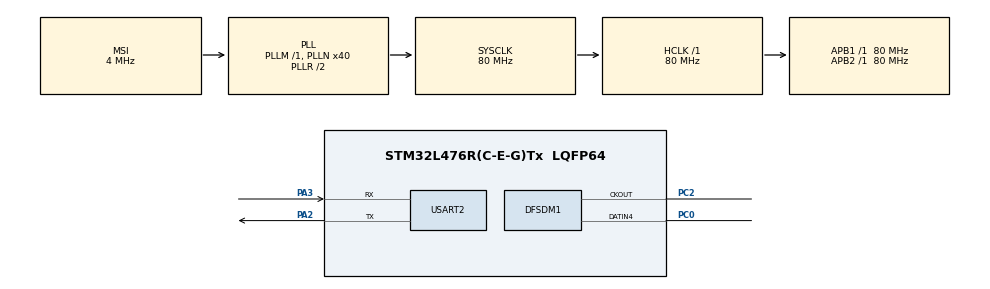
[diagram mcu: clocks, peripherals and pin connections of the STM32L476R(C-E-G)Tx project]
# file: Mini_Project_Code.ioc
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DFSDM1.Divider=32
DFSDM1.DmaMode_reg_FIL0=ENABLE
DFSDM1.FastMode_reg_FIL0=ENABLE
DFSDM1.Filter_regChannel_FIL0=DFSDM_CHANNEL_3
DFSDM1.Filter_regChannel_FIL1=__NULL
DFSDM1.Fosr_FIL0=38
DFSDM1.Iosr_FIL0=4
DFSDM1.SincOrder_FIL0=DFSDM_FILTER_SINC4_ORDER
Dma.DFSDM1_FLT0.0.Direction=DMA_PERIPH_TO_MEMORY
Dma.DFSDM1_FLT0.0.Instance=DMA1_Channel4
Dma.DFSDM1_FLT0.0.MemDataAlignment=DMA_MDATAALIGN_WORD
Dma.DFSDM1_FLT0.0.MemInc=DMA_MINC_ENABLE
Dma.DFSDM1_FLT0.0.Mode=DMA_NORMAL
Dma.DFSDM1_FLT0.0.PeriphDataAlignment=DMA_PDATAALIGN_WORD
Dma.DFSDM1_FLT0.0.PeriphInc=DMA_PINC_DISABLE
Dma.DFSDM1_FLT0.0.Priority=DMA_PRIORITY_LOW
Dma.Request0=DFSDM1_FLT0
Mcu.Family=STM32L4
Mcu.Name=STM32L476R(C-E-G)Tx
Mcu.Package=LQFP64
NVIC.DMA1_Channel4_IRQn=true\:0\:0\:false\:false\:true\:false\:true\:true
NVIC.PriorityGroup=NVIC_PRIORITYGROUP_4
NVIC.TIM2_IRQn=true\:0\:0\:false\:false\:true\:true\:true\:true
PA2.Mode=Asynchronous
PA2.Signal=USART2_TX
PA3.Mode=Asynchronous
PA3.Signal=USART2_RX
PC0.Signal=S_DATAIN4DFSDM1
PC2.Signal=S_CKOUTDFSDM1
ProjectManager.HeapSize=0x200
ProjectManager.StackSize=0x400
ProjectManager.TargetToolchain=CMake
RCC.AHBFreq_Value=80000000
RCC.APB1Freq_Value=80000000
RCC.APB1TimFreq_Value=80000000
RCC.APB2Freq_Value=80000000
RCC.APB2TimFreq_Value=80000000
RCC.CortexFreq_Value=80000000
RCC.HCLKFreq_Value=80000000
RCC.HSE_VALUE=8000000
RCC.HSI_VALUE=16000000
RCC.LSE_VALUE=32768
RCC.MSI_VALUE=4000000
RCC.PLLN=40
RCC.SYSCLKFreq_VALUE=80000000
RCC.SYSCLKSource=RCC_SYSCLKSOURCE_PLLCLK
RCC.VCOOutputFreq_Value=160000000
SH.S_CKOUTDFSDM1.0=DFSDM1_CKOUT,PDM_SPI_Input_from_ch34_and_Internal_Clock
SH.S_DATAIN4DFSDM1.0=DFSDM1_DATIN4,PDM_SPI_Input_from_ch34_and_Internal_Clock
TIM2.Period=19999
TIM2.Prescaler=7999
USART2.VirtualMode-Asynchronous=VM_ASYNC
VP_TIM2_VS_ClockSourceINT.Mode=Internal
board=custom

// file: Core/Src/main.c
/* USER CODE BEGIN Header */
/**
 * @file main.c
 * @brief DSP Exercise
 * @author Philipp Schilk, 2023
 */
/* USER CODE END Header */
#include "main.h"

/* USER CODE BEGIN Includes */
#include "application.h"
#include <stdio.h>
/* USER CODE END Includes */

DFSDM_Filter_HandleTypeDef hdfsdm1_filter0;
DFSDM_Channel_HandleTypeDef hdfsdm1_channel3;
DMA_HandleTypeDef hdma_dfsdm1_flt0;

TIM_HandleTypeDef htim2;

UART_HandleTypeDef huart2;

/* USER CODE BEGIN PV */
volatile int mic_dma_finished_flag;
/* USER CODE END PV */

void SystemClock_Config(void);
static void MX_GPIO_Init(void);
static void MX_DMA_Init(void);
static void MX_USART2_UART_Init(void);
static void MX_DFSDM1_Init(void);
static void MX_TIM2_Init(void);

int main(void)
{

  /* MCU Configuration--------------------------------------------------------*/

  /* Reset of all peripherals, Initializes the Flash interface and the Systick. */
  HAL_Init();

  /* Configure the system clock */
  SystemClock_Config();

  /* Initialize all configured peripherals */
  MX_GPIO_Init();
  MX_DMA_Init();
  MX_USART2_UART_Init();
  MX_DFSDM1_Init();
  MX_TIM2_Init();

  /* Infinite loop */
  /* USER CODE BEGIN WHILE */
  while (1) {
    task();
    /* USER CODE END WHILE */

  }
}

void SystemClock_Config(void)
{
  RCC_OscInitTypeDef RCC_OscInitStruct = {0};
  RCC_ClkInitTypeDef RCC_ClkInitStruct = {0};

  /** Configure the main internal regulator output voltage
  */
  if (HAL_PWREx_ControlVoltageScaling(PWR_REGULATOR_VOLTAGE_SCALE1) != HAL_OK)
  {
    Error_Handler();
  }

  /** Initializes the RCC Oscillators according to the specified parameters
  * in the RCC_OscInitTypeDef structure.
  */
  RCC_OscInitStruct.OscillatorType = RCC_OSCILLATORTYPE_MSI;
  RCC_OscInitStruct.MSIState = RCC_MSI_ON;
  RCC_OscInitStruct.MSICalibrationValue = 0;
  RCC_OscInitStruct.MSIClockRange = RCC_MSIRANGE_6;
  RCC_OscInitStruct.PLL.PLLState = RCC_PLL_ON;
  RCC_OscInitStruct.PLL.PLLSource = RCC_PLLSOURCE_MSI;
  RCC_OscInitStruct.PLL.PLLM = 1;
  RCC_OscInitStruct.PLL.PLLN = 40;
  RCC_OscInitStruct.PLL.PLLP = RCC_PLLP_DIV7;
  RCC_OscInitStruct.PLL.PLLQ = RCC_PLLQ_DIV2;
  RCC_OscInitStruct.PLL.PLLR = RCC_PLLR_DIV2;
  if (HAL_RCC_OscConfig(&RCC_OscInitStruct) != HAL_OK)
  {
    Error_Handler();
  }

  /** Initializes the CPU, AHB and APB buses clocks
  */
  RCC_ClkInitStruct.ClockType = RCC_CLOCKTYPE_HCLK|RCC_CLOCKTYPE_SYSCLK
                              |RCC_CLOCKTYPE_PCLK1|RCC_CLOCKTYPE_PCLK2;
  RCC_ClkInitStruct.SYSCLKSource = RCC_SYSCLKSOURCE_PLLCLK;
  RCC_ClkInitStruct.AHBCLKDivider = RCC_SYSCLK_DIV1;
  RCC_ClkInitStruct.APB1CLKDivider = RCC_HCLK_DIV1;
  RCC_ClkInitStruct.APB2CLKDivider = RCC_HCLK_DIV1;

  if (HAL_RCC_ClockConfig(&RCC_ClkInitStruct, FLASH_LATENCY_4) != HAL_OK)
  {
    Error_Handler();
  }
}

static void MX_DFSDM1_Init(void)
{

  hdfsdm1_filter0.Instance = DFSDM1_Filter0;
  hdfsdm1_filter0.Init.RegularParam.Trigger = DFSDM_FILTER_SW_TRIGGER;
  hdfsdm1_filter0.Init.RegularParam.FastMode = ENABLE;
  hdfsdm1_filter0.Init.RegularParam.DmaMode = ENABLE;
  hdfsdm1_filter0.Init.FilterParam.SincOrder = DFSDM_FILTER_SINC4_ORDER;
  hdfsdm1_filter0.Init.FilterParam.Oversampling = 38;
  hdfsdm1_filter0.Init.FilterParam.IntOversampling = 4;
  if (HAL_DFSDM_FilterInit(&hdfsdm1_filter0) != HAL_OK)
  {
    Error_Handler();
  }
  hdfsdm1_channel3.Instance = DFSDM1_Channel3;
  hdfsdm1_channel3.Init.OutputClock.Activation = ENABLE;
  hdfsdm1_channel3.Init.OutputClock.Selection = DFSDM_CHANNEL_OUTPUT_CLOCK_SYSTEM;
  hdfsdm1_channel3.Init.OutputClock.Divider = 32;
  hdfsdm1_channel3.Init.Input.Multiplexer = DFSDM_CHANNEL_EXTERNAL_INPUTS;
  hdfsdm1_channel3.Init.Input.DataPacking = DFSDM_CHANNEL_STANDARD_MODE;
  hdfsdm1_channel3.Init.Input.Pins = DFSDM_CHANNEL_FOLLOWING_CHANNEL_PINS;
  hdfsdm1_channel3.Init.SerialInterface.Type = DFSDM_CHANNEL_SPI_RISING;
  hdfsdm1_channel3.Init.SerialInterface.SpiClock = DFSDM_CHANNEL_SPI_CLOCK_INTERNAL;
  hdfsdm1_channel3.Init.Awd.FilterOrder = DFSDM_CHANNEL_FASTSINC_ORDER;
  hdfsdm1_channel3.Init.Awd.Oversampling = 1;
  hdfsdm1_channel3.Init.Offset = 0;
  hdfsdm1_channel3.Init.RightBitShift = 0x00;
  if (HAL_DFSDM_ChannelInit(&hdfsdm1_channel3) != HAL_OK)
  {
    Error_Handler();
  }
  if (HAL_DFSDM_FilterConfigRegChannel(&hdfsdm1_filter0, DFSDM_CHANNEL_3, DFSDM_CONTINUOUS_CONV_ON) != HAL_OK)
  {
    Error_Handler();
  }

}

static void MX_TIM2_Init(void)
{

  TIM_ClockConfigTypeDef sClockSourceConfig = {0};
  TIM_MasterConfigTypeDef sMasterConfig = {0};

  htim2.Instance = TIM2;
  htim2.Init.Prescaler = 7999;
  htim2.Init.CounterMode = TIM_COUNTERMODE_UP;
  htim2.Init.Period = 19999;
  htim2.Init.ClockDivision = TIM_CLOCKDIVISION_DIV1;
  htim2.Init.AutoReloadPreload = TIM_AUTORELOAD_PRELOAD_DISABLE;
  if (HAL_TIM_Base_Init(&htim2) != HAL_OK)
  {
    Error_Handler();
  }
  sClockSourceConfig.ClockSource = TIM_CLOCKSOURCE_INTERNAL;
  if (HAL_TIM_ConfigClockSource(&htim2, &sClockSourceConfig) != HAL_OK)
  {
    Error_Handler();
  }
  sMasterConfig.MasterOutputTrigger = TIM_TRGO_RESET;
  sMasterConfig.MasterSlaveMode = TIM_MASTERSLAVEMODE_DISABLE;
  if (HAL_TIMEx_MasterConfigSynchronization(&htim2, &sMasterConfig) != HAL_OK)
  {
    Error_Handler();
  }

}

static void MX_USART2_UART_Init(void)
{

  huart2.Instance = USART2;
  huart2.Init.BaudRate = 115200;
  huart2.Init.WordLength = UART_WORDLENGTH_8B;
  huart2.Init.StopBits = UART_STOPBITS_1;
  huart2.Init.Parity = UART_PARITY_NONE;
  huart2.Init.Mode = UART_MODE_TX_RX;
  huart2.Init.HwFlowCtl = UART_HWCONTROL_NONE;
  huart2.Init.OverSampling = UART_OVERSAMPLING_16;
  huart2.Init.OneBitSampling = UART_ONE_BIT_SAMPLE_DISABLE;
  huart2.AdvancedInit.AdvFeatureInit = UART_ADVFEATURE_NO_INIT;
  if (HAL_UART_Init(&huart2) != HAL_OK)
  {
    Error_Handler();
  }

}

static void MX_DMA_Init(void)
{

  /* DMA controller clock enable */
  __HAL_RCC_DMA1_CLK_ENABLE();

  /* DMA interrupt init */
  /* DMA1_Channel4_IRQn interrupt configuration */
  HAL_NVIC_SetPriority(DMA1_Channel4_IRQn, 0, 0);
  HAL_NVIC_EnableIRQ(DMA1_Channel4_IRQn);

}

static void MX_GPIO_Init(void)
{

  /* GPIO Ports Clock Enable */
  __HAL_RCC_GPIOC_CLK_ENABLE();
  __HAL_RCC_GPIOA_CLK_ENABLE();

}

/* USER CODE BEGIN 4 */
void HAL_DFSDM_FilterRegConvCpltCallback(DFSDM_Filter_HandleTypeDef *hdfsdm_filter) {
  UNUSED(hdfsdm_filter);
  mic_dma_finished_flag = 1;
}
/* USER CODE END 4 */

void Error_Handler(void)
{
  __disable_irq();
  while (1) {
  }
}
